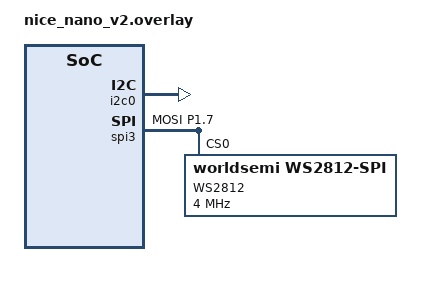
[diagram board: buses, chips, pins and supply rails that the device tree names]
/*
 * Copyright (c) 2024 The ZMK Contributors
 * SPDX-License-Identifier: MIT
 */

/* I2C configuration for trackball */
&i2c0 {
    status = "okay";
};

/* Pinctrl definitions for SPI3 (RGB LED) */
&pinctrl {
    spi3_default: spi3_default {
        group1 {
            psels = <NRF_PSEL(SPIM_MOSI, 1, 7)>;
        };
    };

    spi3_sleep: spi3_sleep {
        group1 {
            psels = <NRF_PSEL(SPIM_MOSI, 1, 7)>;
            low-power-enable;
        };
    };
};

/* LED Strip (WS2812) on extra GPIO P1.07 */
&spi3 {
    compatible = "nordic,nrf-spim";
    status = "okay";
    pinctrl-0 = <&spi3_default>;
    pinctrl-1 = <&spi3_sleep>;
    pinctrl-names = "default", "sleep";

    led_strip: ws2812@0 {
        compatible = "worldsemi,ws2812-spi";
        label = "WS2812";
        reg = <0>;
        spi-max-frequency = <4000000>;
        chain-length = <10>;
        spi-one-frame = <0x70>;
        spi-zero-frame = <0x40>;
        color-mapping = <LED_COLOR_ID_GREEN LED_COLOR_ID_RED LED_COLOR_ID_BLUE>;
    };
};
